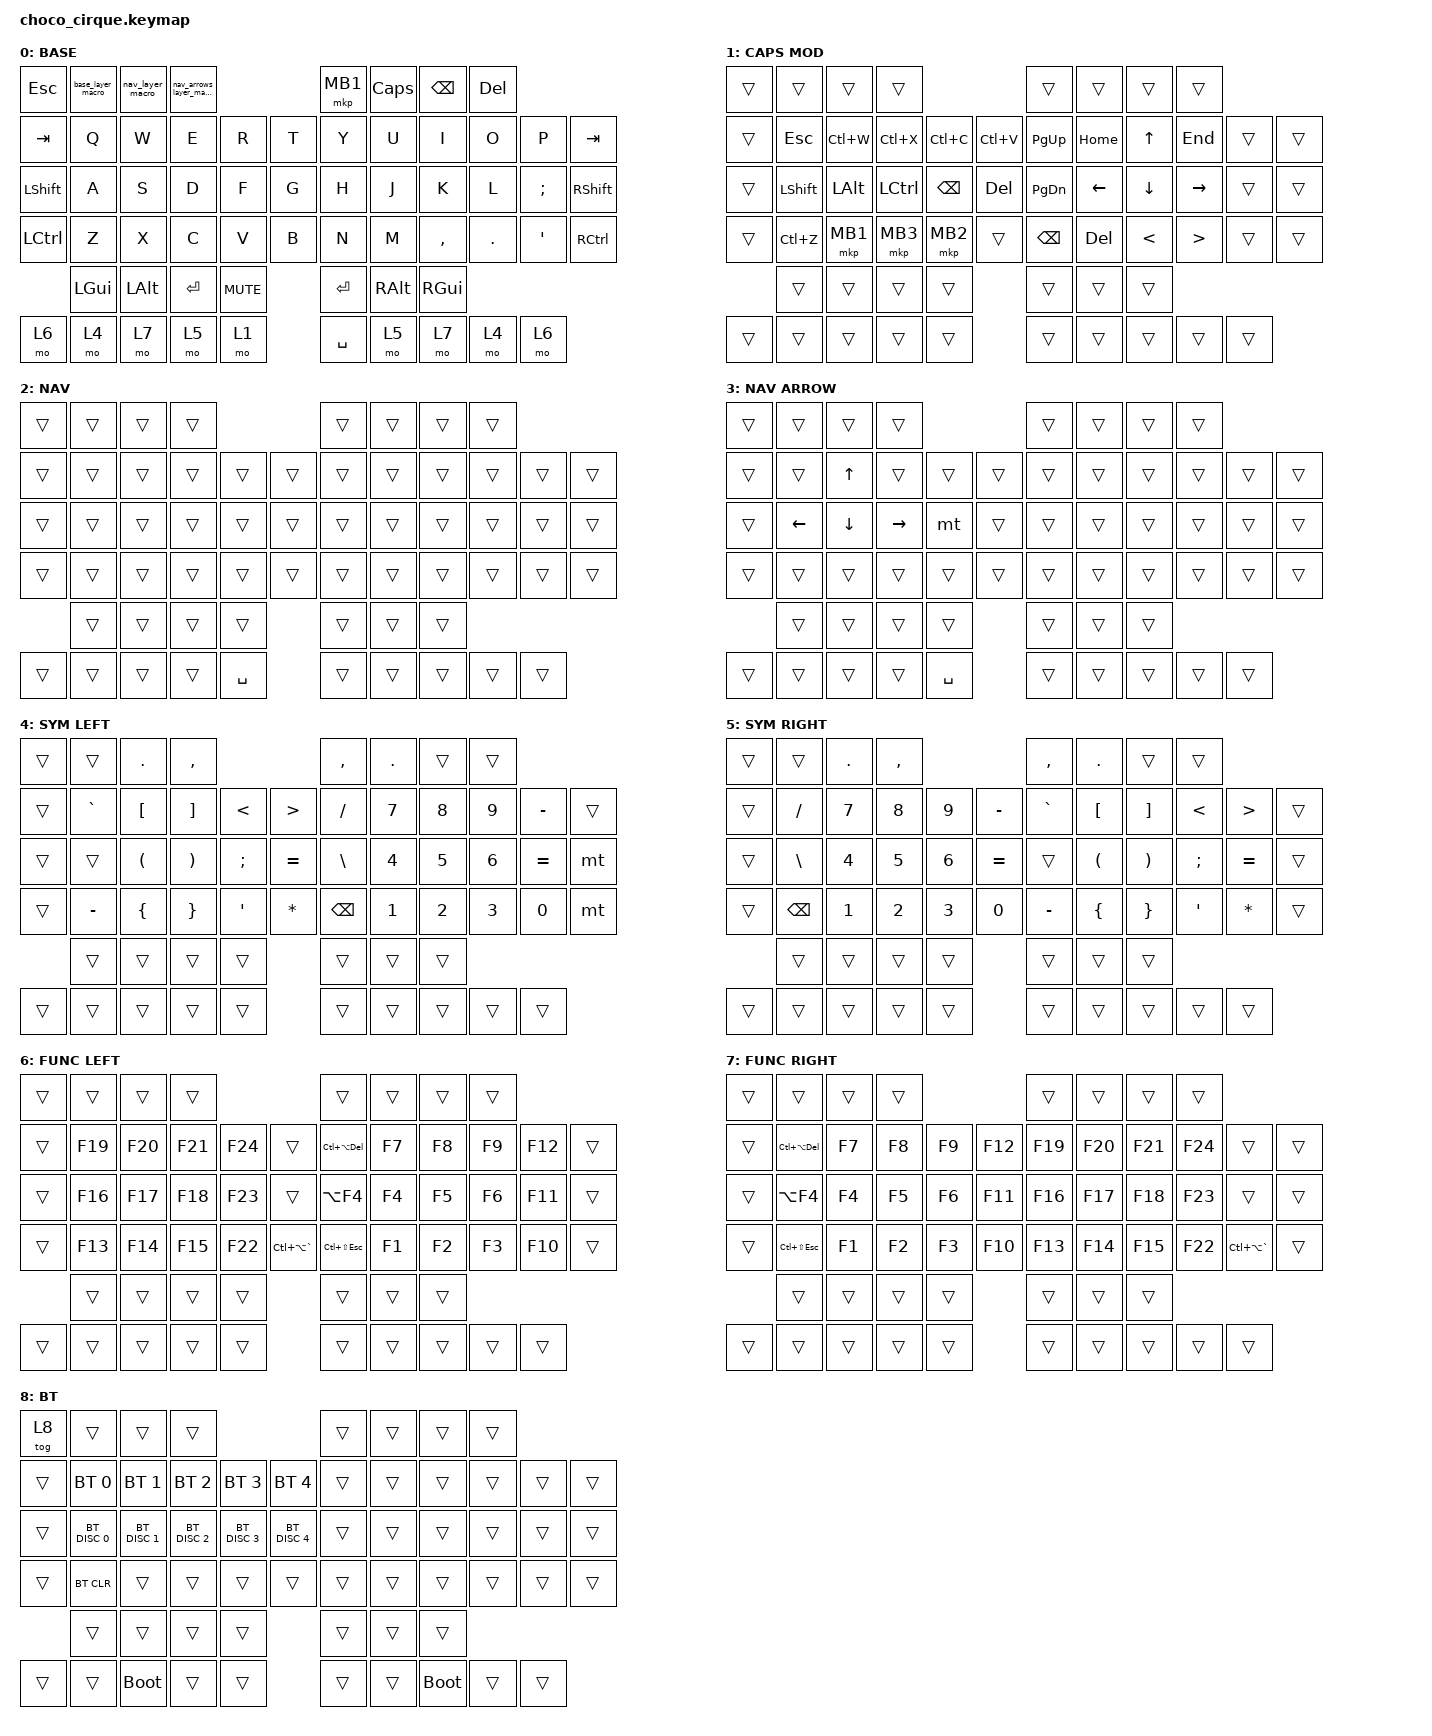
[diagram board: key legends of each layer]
/*
 * Copyright (c) 2020 The ZMK Contributors
 *
 * SPDX-License-Identifier: MIT
 */

#include <behaviors.dtsi>
#include <dt-bindings/zmk/keys.h>
#include <dt-bindings/zmk/bt.h>

/ {

    macros {
        lm: lm {
            compatible = "zmk,behavior-macro-two-param";
            wait-ms = <0>;
            tap-ms = <0>;
            #binding-cells = <2>;
            bindings
                = <&macro_param_1to1>
                , <&macro_press &mo MACRO_PLACEHOLDER>
                , <&macro_param_2to1>
                , <&macro_press &kp MACRO_PLACEHOLDER>
                , <&macro_pause_for_release>
                , <&macro_param_2to1>
                , <&macro_release &kp MACRO_PLACEHOLDER>
                , <&macro_param_1to1>
                , <&macro_release &mo MACRO_PLACEHOLDER>
                ;
        };
    base_layer_macro: base_layer_macro {
        compatible = "zmk,behavior-macro";
        #binding-cells = <0>;
        wait-ms = <30>;
        tap-ms = <40>;
        bindings = <&kp F23 &to 0>;
        };
    nav_layer_macro: nav_layer_macro {
        compatible = "zmk,behavior-macro";
        #binding-cells = <0>;
        wait-ms = <30>;
        tap-ms = <40>;
        bindings = <&kp F24 &to 2>;
        };
    nav_arrows_layer_macro: nav_arrows_layer_macro {
        compatible = "zmk,behavior-macro";
        #binding-cells = <0>;
        wait-ms = <30>;
        tap-ms = <40>;
        bindings = <&kp F24 &to 3>;
        };
    };

    combos {
        compatible = "zmk,combos";

        combo_capsmod_right {
            timeout-ms = <200>;
            key-positions = <56 59>;
            bindings = <&mo 1>;
        };
        combo_bluetooth{
            timeout-ms=<200>;
            key-positions = <1 2 3>;
            bindings = <&tog 8>;
        };
        combo_bluetooth_right{
            timeout-ms=<200>;
            key-positions = <4 5 6>;
            bindings = <&tog 8>;
        };
    };
    keymap {
        compatible = "zmk,keymap";
            default_layer {
                display-name = "BASE";
            bindings = <
&kp ESC	&base_layer_macro	&nav_layer_macro	&nav_arrows_layer_macro						&mkp MB1	&kp CAPS	&kp BSPC	&kp DEL
&kp TAB	&kp Q	&kp W	&kp E	&kp R	&kp T		&kp Y	&kp U	&kp I	&kp O	&kp P	&kp TAB
&kp LSHIFT	&kp A	&kp S	&kp D	&kp F	&kp G		&kp H	&kp J	&kp K	&kp L	&kp SEMI	&kp RSHIFT
&kp LCTRL	&kp Z	&kp X	&kp C	&kp V	&kp B		&kp N	&kp M	&kp COMMA	&kp DOT	&kp SINGLE_QUOTE	&kp RCTRL
		&kp LGUI	&kp LALT	&kp RET	&kp C_MUTE			&kp RET	&kp RALT	&kp RGUI		
	&mo 6	&mo 4	&mo 7	&mo 5	&mo 1			&kp SPACE	&mo 5	&mo 7	&mo 4	&mo 6
            >;

                sensor-bindings = <&inc_dec_kp C_VOL_UP C_VOL_DN>;
            };

            capsmod_layer {
                display-name = "CAPS MOD";
            bindings = <
&trans	&trans	&trans	&trans						&trans	&trans	&trans	&trans
&trans	&kp ESC	&kp LC(W)	&kp LC(X)	&kp LC(C)	&kp LC(V)		&kp PAGE_UP	&kp HOME	&kp UP_ARROW	&kp END	&trans	&trans
&trans	&kp LSHIFT	&kp LALT	&kp LCTRL	&kp BSPC	&kp DEL		&kp PAGE_DOWN	&kp LEFT_ARROW	&kp DOWN_ARROW	&kp RIGHT_ARROW	&trans	&trans
&trans	&kp LC(Z)	&mkp MB1	&mkp MB3	&mkp MB2	&trans		&kp BSPC	&kp DEL	&kp LESS_THAN	&kp GREATER_THAN	&trans	&trans
		&trans	&trans	&trans	&trans			&trans	&trans	&trans		
	&trans	&trans	&trans	&trans	&trans			&trans	&trans	&trans	&trans	&trans
            >;
                sensor-bindings = <&inc_dec_kp C_VOL_UP C_VOL_DN>;
            };

            navigation_layer {
                display-name = "NAV";
            bindings = <
&trans	&trans	&trans	&trans						&trans	&trans	&trans	&trans
&trans	&trans	&trans	&trans	&trans	&trans		&trans	&trans	&trans	&trans	&trans	&trans
&trans	&trans	&trans	&trans	&trans	&trans		&trans	&trans	&trans	&trans	&trans	&trans
&trans	&trans	&trans	&trans	&trans	&trans		&trans	&trans	&trans	&trans	&trans	&trans
		&trans	&trans	&trans	&trans			&trans	&trans	&trans		
	&trans	&trans	&trans	&trans	&kp SPACE			&trans	&trans	&trans	&trans	&trans
            >;

                sensor-bindings = <&inc_dec_kp C_VOL_UP C_VOL_DN>;
            };

            nav_arrow_layer {
                display-name = "NAV ARROW";
            bindings = <
&trans	&trans	&trans	&trans						&trans	&trans	&trans	&trans
&trans	&trans	&kp UP_ARROW	&trans	&trans	&trans		&trans	&trans	&trans	&trans	&trans	&trans
&trans	&kp LEFT_ARROW	&kp DOWN_ARROW	&kp RIGHT_ARROW	&mt  	&trans		&trans	&trans	&trans	&trans	&trans	&trans
&trans	&trans	&trans	&trans	&trans	&trans		&trans	&trans	&trans	&trans	&trans	&trans
		&trans	&trans	&trans	&trans			&trans	&trans	&trans		
	&trans	&trans	&trans	&trans	&kp SPACE			&trans	&trans	&trans	&trans	&trans
            >;

                sensor-bindings = <&inc_dec_kp C_VOL_UP C_VOL_DN>;
            };

            symbol_left_layer {
                display-name = "SYM LEFT";
            bindings = <
&trans	&trans	&kp DOT	&kp COMMA						&kp COMMA	&kp DOT	&trans	&trans
&trans	&kp GRAVE	&kp LEFT_BRACKET	&kp RIGHT_BRACKET	&kp LESS_THAN	&kp GREATER_THAN		&kp SLASH	&kp NUMBER_7	&kp NUMBER_8	&kp NUMBER_9	&kp MINUS	&trans
&trans	&trans	&kp LEFT_PARENTHESIS	&kp RIGHT_PARENTHESIS	&kp SEMICOLON	&kp EQUAL		&kp BACKSLASH	&kp NUMBER_4	&kp NUMBER_5	&kp NUMBER_6	&kp EQUAL	&mt  
&trans	&kp MINUS	&kp LEFT_BRACE	&kp RIGHT_BRACE	&kp SINGLE_QUOTE	&kp ASTERISK		&kp BSPC	&kp NUMBER_1	&kp NUMBER_2	&kp NUMBER_3	&kp NUMBER_0	&mt  
		&trans	&trans	&trans	&trans			&trans	&trans	&trans		
	&trans	&trans	&trans	&trans	&trans			&trans	&trans	&trans	&trans	&trans
            >;

                sensor-bindings = <&inc_dec_kp C_VOL_UP C_VOL_DN>;
            };

            symbol_right_layer {
                display-name = "SYM RIGHT";
            bindings = <
&trans	&trans	&kp DOT	&kp COMMA						&kp COMMA	&kp DOT	&trans	&trans
&trans	&kp SLASH	&kp NUMBER_7	&kp NUMBER_8	&kp NUMBER_9	&kp MINUS		&kp GRAVE	&kp LEFT_BRACKET	&kp RIGHT_BRACKET	&kp LESS_THAN	&kp GREATER_THAN	&trans
&trans	&kp BACKSLASH	&kp NUMBER_4	&kp NUMBER_5	&kp NUMBER_6	&kp EQUAL		&trans	&kp LEFT_PARENTHESIS	&kp RIGHT_PARENTHESIS	&kp SEMICOLON	&kp EQUAL	&trans
&trans	&kp BSPC	&kp NUMBER_1	&kp NUMBER_2	&kp NUMBER_3	&kp NUMBER_0		&kp MINUS	&kp LEFT_BRACE	&kp RIGHT_BRACE	&kp SINGLE_QUOTE	&kp ASTERISK	&trans
		&trans	&trans	&trans	&trans			&trans	&trans	&trans		
	&trans	&trans	&trans	&trans	&trans			&trans	&trans	&trans	&trans	&trans
            >;

                sensor-bindings = <&inc_dec_kp C_VOL_UP C_VOL_DN>;
            };

            func_left_layer {
                display-name = "FUNC LEFT";
            bindings = <
&trans	&trans	&trans	&trans						&trans	&trans	&trans	&trans
&trans	&kp F19	&kp F20	&kp F21	&kp F24	&trans		&kp LC(LA(DEL))	&kp F7	&kp F8	&kp F9	&kp F12	&trans
&trans	&kp F16	&kp F17	&kp F18	&kp F23	&trans		&kp LA(F4)	&kp F4	&kp F5	&kp F6	&kp F11	&trans
&trans	&kp F13	&kp F14	&kp F15	&kp F22	&kp LC(LA(GRAVE))		&kp LC(LS(ESC))	&kp F1	&kp F2	&kp F3	&kp F10	&trans
		&trans	&trans	&trans	&trans			&trans	&trans	&trans		
	&trans	&trans	&trans	&trans	&trans			&trans	&trans	&trans	&trans	&trans
            >;

                sensor-bindings = <&inc_dec_kp C_VOL_UP C_VOL_DN>;
            };

            func_right_layer {
                display-name = "FUNC RIGHT";
            bindings = <
&trans	&trans	&trans	&trans						&trans	&trans	&trans	&trans
&trans	&kp LC(LA(DEL))	&kp F7	&kp F8	&kp F9	&kp F12		&kp F19	&kp F20	&kp F21	&kp F24	&trans	&trans
&trans	&kp LA(F4)	&kp F4	&kp F5	&kp F6	&kp F11		&kp F16	&kp F17	&kp F18	&kp F23	&trans	&trans
&trans	&kp LC(LS(ESC))	&kp F1	&kp F2	&kp F3	&kp F10		&kp F13	&kp F14	&kp F15	&kp F22	&kp LC(LA(GRAVE))	&trans
		&trans	&trans	&trans	&trans			&trans	&trans	&trans		
	&trans	&trans	&trans	&trans	&trans			&trans	&trans	&trans	&trans	&trans
            >;

                sensor-bindings = <&inc_dec_kp C_VOL_UP C_VOL_DN>;
            };

            bt_layer {
                display-name = "BT";
            bindings = <
&tog 8	&trans	&trans	&trans						&trans	&trans	&trans	&trans
&trans	&bt BT_SEL 0	&bt BT_SEL 1	&bt BT_SEL 2	&bt BT_SEL 3	&bt BT_SEL 4		&trans	&trans	&trans	&trans	&trans	&trans
&trans	&bt BT_DISC 0	&bt BT_DISC 1	&bt BT_DISC 2	&bt BT_DISC 3	&bt BT_DISC 4		&trans	&trans	&trans	&trans	&trans	&trans
&trans	&bt BT_CLR	&trans	&trans	&trans	&trans		&trans	&trans	&trans	&trans	&trans	&trans
		&trans	&trans	&trans	&trans			&trans	&trans	&trans		
	&trans	&trans	&bootloader	&trans	&trans			&trans	&trans	&bootloader	&trans	&trans
            >;

                sensor-bindings = <&inc_dec_kp C_VOL_UP C_VOL_DN>;
            };


    };
};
